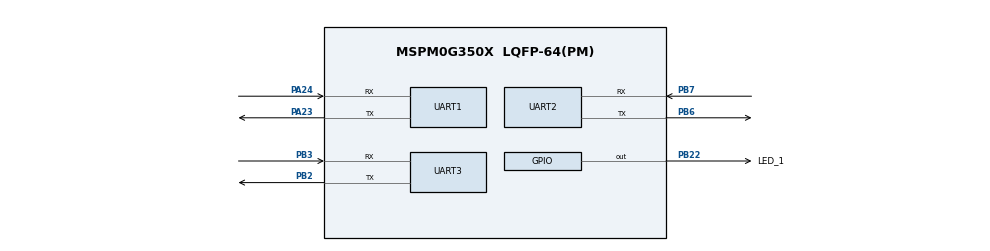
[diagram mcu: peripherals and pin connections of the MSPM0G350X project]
/**
 * @cliArgs --device "MSPM0G350X" --part "Default" --package "LQFP-64(PM)" --product "mspm0_sdk@2.05.01.00"
 * @versions {"tool":"1.21.0+3721"}
 */

/**
 * Import the modules used in this configuration.
 */
const GPIO   = scripting.addModule("/ti/driverlib/GPIO", {}, false);
const GPIO1  = GPIO.addInstance();
const SYSCTL = scripting.addModule("/ti/driverlib/SYSCTL");
const UART   = scripting.addModule("/ti/driverlib/UART", {}, false);
const UART1  = UART.addInstance();
const UART2  = UART.addInstance();
const UART3  = UART.addInstance();

/**
 * Write custom configuration values to the imported modules.
 */
const divider9       = system.clockTree["UDIV"];
divider9.divideValue = 2;

const multiplier2         = system.clockTree["PLL_QDIV"];
multiplier2.multiplyValue = 5;

const mux8       = system.clockTree["HSCLKMUX"];
mux8.inputSelect = "HSCLKMUX_SYSPLL0";

GPIO1.$name                         = "GPIO_GRP_0";
GPIO1.associatedPins[0].$name       = "LED_1";
GPIO1.associatedPins[0].pin.$assign = "PB22";

const Board = scripting.addModule("/ti/driverlib/Board", {}, false);

const mfclkGate  = system.clockTree["MFCLKGATE"];
mfclkGate.enable = true;

SYSCTL.forceDefaultClkConfig = true;
SYSCTL.clockTreeEn           = true;

UART1.$name                            = "stepMotor1";
UART1.uartClkSrc                        = "MFCLK";
UART1.targetBaudRate                   = 115200;
UART1.enableFIFO                       = true;
UART1.peripheral.$assign               = "UART2";
UART1.peripheral.rxPin.$assign         = "PA24";
UART1.peripheral.txPin.$assign         = "PA23";
UART1.txPinConfig.$name                = "ti_driverlib_gpio_GPIOPinGeneric0";
UART1.txPinConfig.direction            = scripting.forceWrite("OUTPUT");
UART1.txPinConfig.hideOutputInversion  = scripting.forceWrite(false);
UART1.txPinConfig.onlyInternalResistor = scripting.forceWrite(false);
UART1.txPinConfig.passedPeripheralType = scripting.forceWrite("Digital");
UART1.txPinConfig.enableConfig         = true;
UART1.rxPinConfig.$name                = "ti_driverlib_gpio_GPIOPinGeneric1";
UART1.rxPinConfig.hideOutputInversion  = scripting.forceWrite(false);
UART1.rxPinConfig.onlyInternalResistor = scripting.forceWrite(false);
UART1.rxPinConfig.passedPeripheralType = scripting.forceWrite("Digital");
UART1.rxPinConfig.enableConfig         = true;

UART2.$name                            = "stepMotor2";
UART2.uartClkSrc                        = "MFCLK";
UART2.targetBaudRate                   = 115200;
UART2.enableFIFO                       = true;
UART2.peripheral.$assign               = "UART1";
UART2.peripheral.rxPin.$assign         = "PB7";
UART2.peripheral.txPin.$assign         = "PB6";
UART2.txPinConfig.$name                = "ti_driverlib_gpio_GPIOPinGeneric2";
UART2.txPinConfig.direction            = scripting.forceWrite("OUTPUT");
UART2.txPinConfig.hideOutputInversion  = scripting.forceWrite(false);
UART2.txPinConfig.onlyInternalResistor = scripting.forceWrite(false);
UART2.txPinConfig.passedPeripheralType = scripting.forceWrite("Digital");
UART2.rxPinConfig.$name                = "ti_driverlib_gpio_GPIOPinGeneric3";
UART2.rxPinConfig.hideOutputInversion  = scripting.forceWrite(false);
UART2.rxPinConfig.onlyInternalResistor = scripting.forceWrite(false);
UART2.rxPinConfig.passedPeripheralType = scripting.forceWrite("Digital");

UART3.$name                            = "maxicam";
UART3.targetBaudRate                   = 115200;
UART3.enableFIFO                       = true;
UART3.rxFifoThreshold                  = "DL_UART_RX_FIFO_LEVEL_ONE_ENTRY";
UART3.rxTimeoutValue                   = 15;
UART3.enabledInterrupts                = ["RX", "RX_TIMEOUT_ERROR"];
UART3.peripheral.$assign               = "UART3";
UART3.peripheral.rxPin.$assign         = "PB3";
UART3.peripheral.txPin.$assign         = "PB2";
UART3.txPinConfig.$name                = "ti_driverlib_gpio_GPIOPinGeneric4";
UART3.txPinConfig.direction            = scripting.forceWrite("OUTPUT");
UART3.txPinConfig.hideOutputInversion  = scripting.forceWrite(false);
UART3.txPinConfig.onlyInternalResistor = scripting.forceWrite(false);
UART3.txPinConfig.passedPeripheralType = scripting.forceWrite("Digital");
UART3.rxPinConfig.$name                = "ti_driverlib_gpio_GPIOPinGeneric5";
UART3.rxPinConfig.hideOutputInversion  = scripting.forceWrite(false);
UART3.rxPinConfig.onlyInternalResistor = scripting.forceWrite(false);
UART3.rxPinConfig.passedPeripheralType = scripting.forceWrite("Digital");

/**
 * Pinmux solution for unlocked pins/peripherals. This ensures that minor changes to the automatic solver in a future
 * version of the tool will not impact the pinmux you originally saw.  These lines can be completely deleted in order to
 * re-solve from scratch.
 */
Board.peripheral.$suggestSolution          = "DEBUGSS";
Board.peripheral.swclkPin.$suggestSolution = "PA20";
Board.peripheral.swdioPin.$suggestSolution = "PA19";
